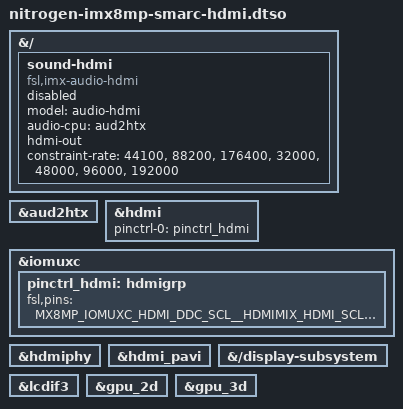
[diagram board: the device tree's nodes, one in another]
// SPDX-License-Identifier: LicenseRef-Ezurio-Clause
/*
 * Copyright 2021 Ezurio
 */

/dts-v1/;
/plugin/;

#include "imx8mp-pinfunc.h"

&{/} {
    sound-hdmi {
        compatible = "fsl,imx-audio-hdmi";
        model = "audio-hdmi";
        audio-cpu = <&aud2htx>;
        hdmi-out;
        constraint-rate = <44100>,
                <88200>,
                <176400>,
                <32000>,
                <48000>,
                <96000>,
                <192000>;
        status = "disabled";
    };
};

&aud2htx {
	status = "okay";
};

&hdmi {
	pinctrl-names = "default";
	pinctrl-0 = <&pinctrl_hdmi>;
	status = "okay";
};

&iomuxc {
	pinctrl_hdmi: hdmigrp {
		fsl,pins = <
			MX8MP_IOMUXC_HDMI_DDC_SCL__HDMIMIX_HDMI_SCL	0x400001c3
			MX8MP_IOMUXC_HDMI_DDC_SDA__HDMIMIX_HDMI_SDA	0x400001c3
			MX8MP_IOMUXC_HDMI_HPD__HDMIMIX_HDMI_HPD		0x40000019
			MX8MP_IOMUXC_HDMI_CEC__HDMIMIX_HDMI_CEC		0x40000019
		>;
	};
};

&hdmiphy {
	status = "okay";
};

&hdmi_pavi {
	status = "okay";
};

&{/display-subsystem} {
	status = "okay";
};

&lcdif3 {
	status = "okay";
};

&gpu_2d {
	status = "okay";
};

&gpu_3d {
	status = "okay";
};
